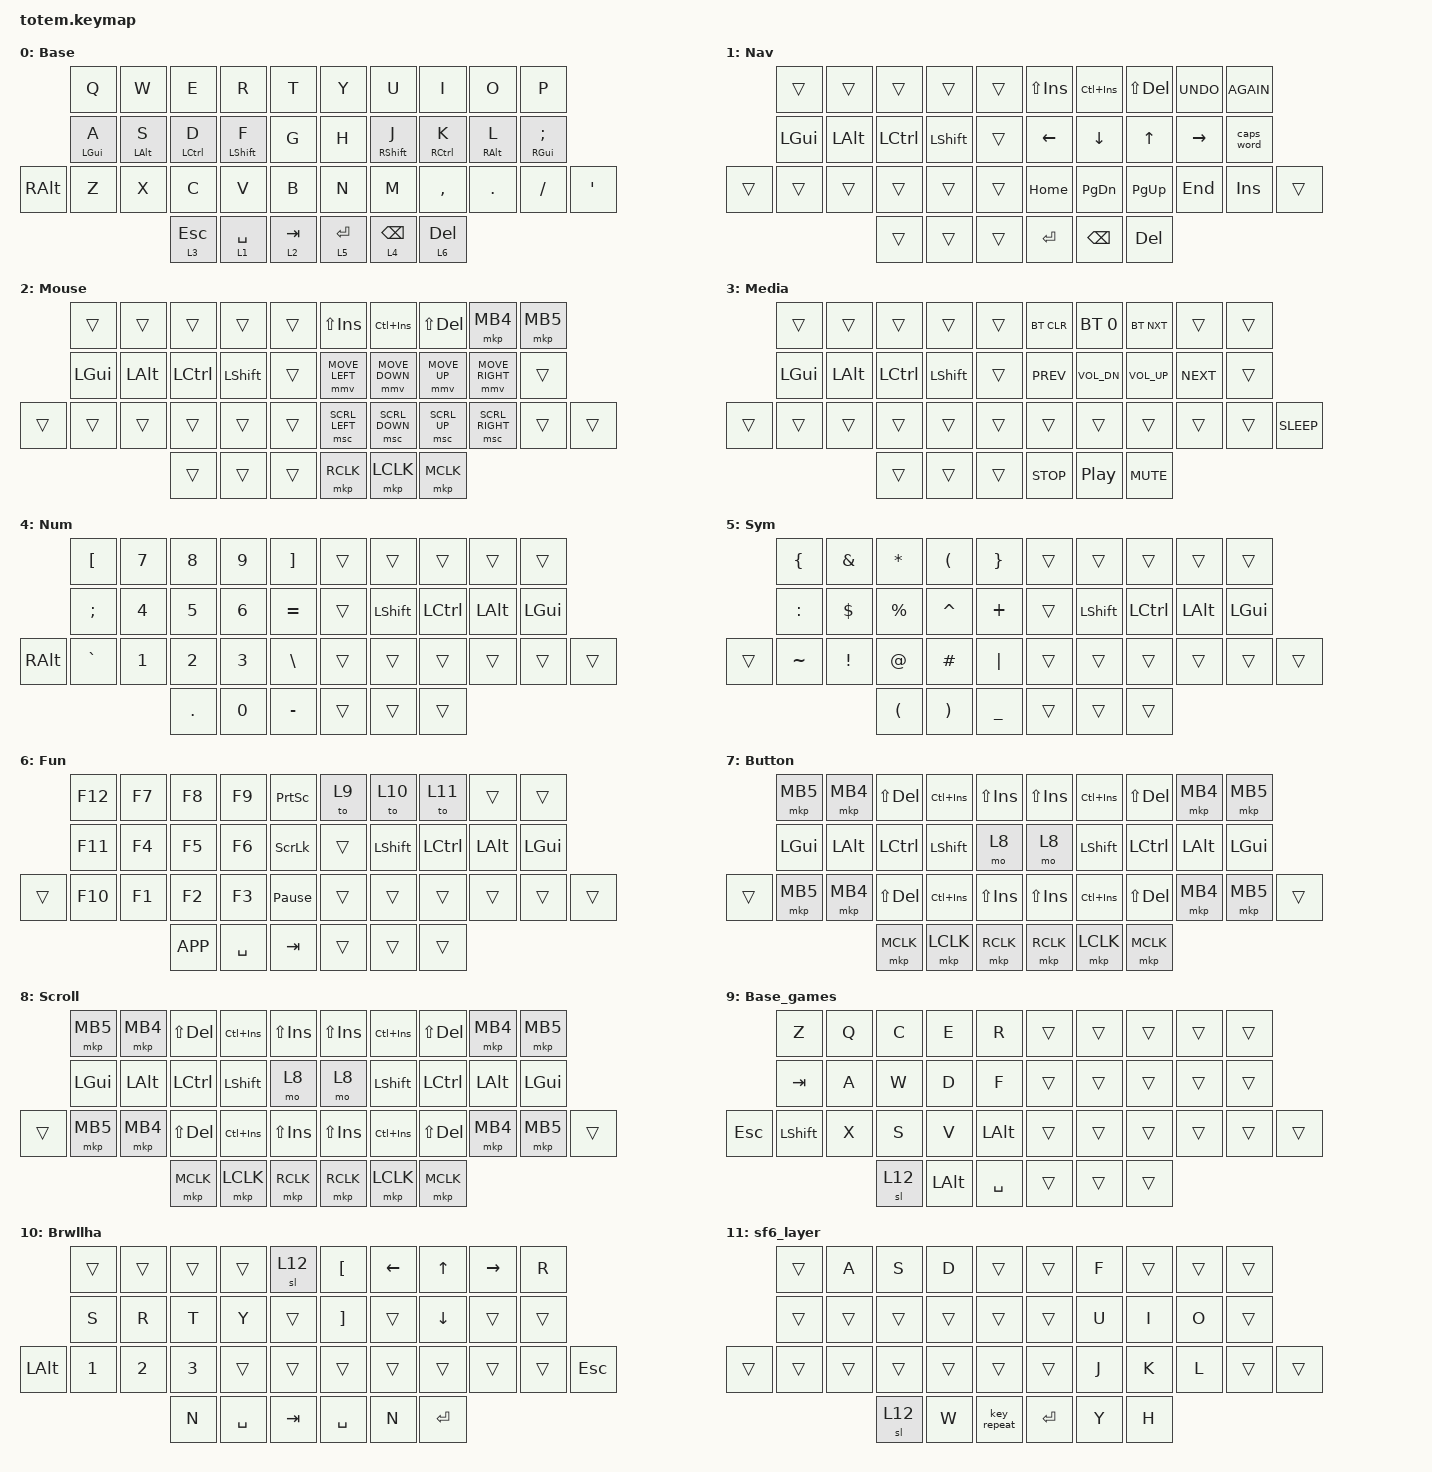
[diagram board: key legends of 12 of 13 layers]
//
//                                                        ▀▀▀▀▀     ▀▀▀▀▀          ▀▀█▀▀
//                                                        ▄▀▀▀▄  ▄  ▄▀▀▀▄  ▄  ▄▀▀▀▄  █  ▄▀▀▀▄
//                                                        █   █  █  █   █  █  █   █  █  █   █
//                                                         ▀▀▀   █   ▀▀▀   █   ▀▀▀   ▀   ▀▀▀
//                                                               █      ▄▄▄█▄▄▄    █   █  
//                                                               ▀      █  █  █     █▄█
//                                                             ▀▀▀▀▀    █  █  █      ▀
//                                                                      ▀  ▀  ▀
//
// ▄▄▄▄▄▄▄▄▄▄▄▄▄▄▄▄▄▄▄▄▄▄▄▄▄▄▄▄▄▄▄▄▄▄▄▄▄▄▄▄▄▄▄▄▄▄▄▄▄▄▄▄▄▄▄▄▄▄▄▄▄▄▄▄▄▄▄▄▄▄▄▄▄▄▄▄▄▄▄▄▄▄▄▄▄▄▄▄▄▄▄▄▄▄▄▄▄▄▄▄▄▄▄▄▄▄▄▄▄▄▄▄▄▄▄▄▄▄▄▄▄▄▄▄▄▄▄▄▄▄▄▄▄▄▄▄▄▄▄▄▄▄▄▄▄▄▄▄▄

#include <behaviors.dtsi>
#include <dt-bindings/zmk/bt.h>
#include <dt-bindings/zmk/keys.h>
#include <dt-bindings/zmk/pointing.h>

#define BASE        0
#define NAV         1
#define MOUSE       2
#define MEDIA       3
#define NUM         4
#define SYM         5
#define FUN         6
#define BUTTON      7
#define BASE_GAMES  9
#define BRWLLHA    10
#define GAME_PLUS  11

// Key position definitions for 38-key Totem layout

#define KEYS_L 0 1 2 3 4 10 11 12 13 14 20 21 22 23 24 25  // left hand
#define KEYS_R 5 6 7 8 9 15 16 17 18 19 26 27 28 29 30 31  // right hand
#define THUMBS 32 33 34 35 36 37                           // thumbs

&mt {
    quick-tap-ms = <100>;
    global-quick-tap;
    flavor = "tap-preferred";
    tapping-term-ms = <170>;
};

&lt {
    tapping-term-ms = <240>;
    flavor = "balanced";
    quick-tap-ms = <150>;
};

/ {
    behaviors {
        // Timeless homerow mods for left hand
        // require-prior-idle-ms = 10500 / WPM (adjust based on typing speed)
        // Same-hand modifiers enabled (no hold-trigger restrictions)

        hml: homerow_mods_left {
            compatible = "zmk,behavior-hold-tap";
            label = "HOMEROW_MODS_LEFT";
            #binding-cells = <2>;
            flavor = "tap-preferred";
            tapping-term-ms = <250>;
            quick-tap-ms = <165>;
            require-prior-idle-ms = <20>;
            bindings = <&kp>, <&kp>;
        };

        // Timeless homerow mods for right hand
        // Urob's timeless config: opposite hand trigger only

        hmr: homerow_mods_right {
            compatible = "zmk,behavior-hold-tap";
            label = "HOMEROW_MODS_RIGHT";
            #binding-cells = <2>;
            flavor = "tap-preferred";
            tapping-term-ms = <250>;
            quick-tap-ms = <165>;
            require-prior-idle-ms = <20>;
            bindings = <&kp>, <&kp>;

            hold-trigger-key-positions = <KEYS_L THUMBS>;
            hold-trigger-on-release;
        };
    };

    combos {
        compatible = "zmk,combos";

        shift_caps_word_combo {
            bindings = <&caps_word>;
            key-positions = <13 16>;
            timeout-ms = <100>;
            require-prior-idle-ms = <150>;
            layers = <0>;
        };
    };

    keymap {
        compatible = "zmk,keymap";

        base_layer {
            display-name = "Base";
            bindings = <
               &kp Q        &kp W        &kp E         &kp R         &kp T        &kp Y      &kp U         &kp I         &kp O        &kp P
               &hml LGUI A  &hml LALT S  &hml LCTRL D  &hml LSHFT F  &kp G        &kp H      &hmr RSHFT J  &hmr RCTRL K  &hmr RALT L  &hmr RGUI SEMICOLON
&kp RIGHT_ALT  &kp Z        &kp X        &kp C         &kp V         &kp B        &kp N      &kp M         &kp COMMA     &kp DOT      &kp SLASH            &kp SQT
                                         &lt 3 ESC     &lt 1 SPACE   &lt 2 TAB    &lt 5 RET  &lt 4 BSPC    &lt 6 DEL
            >;
        };

        nav_layer {
            display-name = "Nav";
            bindings = <
        &trans    &trans    &trans     &trans     &trans    &kp LS(INS)  &kp LC(INS)  &kp LS(DEL)  &kp K_UNDO  &kp K_AGAIN
        &kp LGUI  &kp LALT  &kp LCTRL  &kp LSHFT  &trans    &kp LEFT     &kp DOWN     &kp UP       &kp RIGHT   &caps_word
&trans  &trans    &trans    &trans     &trans     &trans    &kp HOME     &kp PG_DN    &kp PG_UP    &kp END     &kp INS      &trans
                            &trans     &trans     &trans    &kp RET      &kp BSPC     &kp DEL
            >;
        };

        mouse_layer {
            display-name = "Mouse";
            bindings = <
        &trans    &trans    &trans     &trans     &trans    &kp LS(INS)     &kp LC(INS)     &kp LS(DEL)   &mkp MB4         &mkp MB5
        &kp LGUI  &kp LALT  &kp LCTRL  &kp LSHFT  &trans    &mmv MOVE_LEFT  &mmv MOVE_DOWN  &mmv MOVE_UP  &mmv MOVE_RIGHT  &trans
&trans  &trans    &trans    &trans     &trans     &trans    &msc SCRL_LEFT  &msc SCRL_DOWN  &msc SCRL_UP  &msc SCRL_RIGHT  &trans    &trans
                            &trans     &trans     &trans    &mkp RCLK       &mkp LCLK       &mkp MCLK
            >;
        };

        media_layer {
            display-name = "Media";
            bindings = <
        &trans    &trans    &trans     &trans     &trans    &bt BT_CLR  &bt BT_SEL 0  &bt BT_NXT    &trans      &trans
        &kp LGUI  &kp LALT  &kp LCTRL  &kp LSHFT  &trans    &kp C_PREV  &kp C_VOL_DN  &kp C_VOL_UP  &kp C_NEXT  &trans
&trans  &trans    &trans    &trans     &trans     &trans    &trans      &trans        &trans        &trans      &trans  &kp C_SLEEP
                            &trans     &trans     &trans    &kp C_STOP  &kp C_PP      &kp C_MUTE
            >;
        };

        num_layer {
            display-name = "Num";
            bindings = <
          &kp LBKT   &kp N7  &kp N8   &kp N9  &kp RBKT     &trans  &trans     &trans     &trans    &trans
          &kp SEMI   &kp N4  &kp N5   &kp N6  &kp EQUAL    &trans  &kp LSHFT  &kp LCTRL  &kp LALT  &kp LGUI
&kp RALT  &kp GRAVE  &kp N1  &kp N2   &kp N3  &kp BSLH     &trans  &trans     &trans     &trans    &trans    &trans
                             &kp DOT  &kp N0  &kp MINUS    &trans  &trans     &trans
            >;
        };

        sym_layer {
            display-name = "Sym";
            bindings = <
        &kp LBRC   &kp AMPS  &kp ASTRK  &kp LPAR   &kp RBRC     &trans  &trans     &trans     &trans    &trans
        &kp COLON  &kp DLLR  &kp PRCNT  &kp CARET  &kp PLUS     &trans  &kp LSHFT  &kp LCTRL  &kp LALT  &kp LGUI
&trans  &kp TILDE  &kp EXCL  &kp AT     &kp HASH   &kp PIPE     &trans  &trans     &trans     &trans    &trans    &trans
                             &kp LPAR   &kp RPAR   &kp UNDER    &trans  &trans     &trans
            >;
        };

        fun_layer {
            display-name = "Fun";
            bindings = <
        &kp F12  &kp F7  &kp F8     &kp F9     &kp PSCRN          &to 9   &to 10     &to 11     &trans    &trans
        &kp F11  &kp F4  &kp F5     &kp F6     &kp SLCK           &trans  &kp LSHFT  &kp LCTRL  &kp LALT  &kp LGUI
&trans  &kp F10  &kp F1  &kp F2     &kp F3     &kp PAUSE_BREAK    &trans  &trans     &trans     &trans    &trans    &trans
                         &kp K_APP  &kp SPACE  &kp TAB            &trans  &trans     &trans
            >;
        };

        button_layer {
            display-name = "Button";
            bindings = <
        &mkp MB5  &mkp MB4  &kp LS(DEL)  &kp LC(INS)  &kp LS(INS)    &kp LS(INS)  &kp LC(INS)  &kp LS(DEL)  &mkp MB4  &mkp MB5
        &kp LGUI  &kp LALT  &kp LCTRL    &kp LSHFT    &mo 8          &mo 8        &kp LSHFT    &kp LCTRL    &kp LALT  &kp LGUI
&trans  &mkp MB5  &mkp MB4  &kp LS(DEL)  &kp LC(INS)  &kp LS(INS)    &kp LS(INS)  &kp LC(INS)  &kp LS(DEL)  &mkp MB4  &mkp MB5  &trans
                            &mkp MCLK    &mkp LCLK    &mkp RCLK      &mkp RCLK    &mkp LCLK    &mkp MCLK
            >;
        };

        scroll_layer {
            display-name = "Scroll";
            bindings = <
        &mkp MB5  &mkp MB4  &kp LS(DEL)  &kp LC(INS)  &kp LS(INS)    &kp LS(INS)  &kp LC(INS)  &kp LS(DEL)  &mkp MB4  &mkp MB5
        &kp LGUI  &kp LALT  &kp LCTRL    &kp LSHFT    &mo 8          &mo 8        &kp LSHFT    &kp LCTRL    &kp LALT  &kp LGUI
&trans  &mkp MB5  &mkp MB4  &kp LS(DEL)  &kp LC(INS)  &kp LS(INS)    &kp LS(INS)  &kp LC(INS)  &kp LS(DEL)  &mkp MB4  &mkp MB5  &trans
                            &mkp MCLK    &mkp LCLK    &mkp RCLK      &mkp RCLK    &mkp LCLK    &mkp MCLK
            >;
        };

        base_games_layer {
            display-name = "Base_games";
            bindings = <
            &kp Z       &kp Q  &kp C   &kp E     &kp R           &trans  &trans  &trans  &trans  &trans
            &kp TAB     &kp A  &kp W   &kp D     &kp F           &trans  &trans  &trans  &trans  &trans
&kp ESCAPE  &kp LSHIFT  &kp X  &kp S   &kp V     &kp LEFT_ALT    &trans  &trans  &trans  &trans  &trans  &trans
                               &sl 12  &kp LALT  &kp SPACE       &trans  &trans  &trans
            >;
        };

        brwllha_layer {
            display-name = "Brwllha";
            bindings = <
          &trans        &trans        &trans        &trans     &sl 12     &kp LEFT_BRACKET   &kp LEFT_ARROW  &kp UP_ARROW    &kp RIGHT_ARROW  &kp R
          &kp S         &kp R         &kp T         &kp Y      &trans     &kp RIGHT_BRACKET  &trans          &kp DOWN_ARROW  &trans           &trans
&kp LALT  &kp NUMBER_1  &kp NUMBER_2  &kp NUMBER_3  &trans     &trans     &trans             &trans          &trans          &trans           &trans  &kp ESC
                                      &kp N         &kp SPACE  &kp TAB    &kp SPACE          &kp N           &kp ENTER
            >;
        };

        sf6_layer {
            bindings = <
        &trans  &kp A   &kp S   &kp D   &trans         &trans     &kp F  &trans  &trans  &trans
        &trans  &trans  &trans  &trans  &trans         &trans     &kp U  &kp I   &kp O   &trans
&trans  &trans  &trans  &trans  &trans  &trans         &trans     &kp J  &kp K   &kp L   &trans  &trans
                        &sl 12  &kp W   &key_repeat    &kp ENTER  &kp Y  &kp H
            >;
        };

        game_plus_layer {
            display-name = "Game_plus";
            bindings = <
       &kp NUMBER_1  &kp NUMBER_2  &kp NUMBER_3  &kp NUMBER_4  &kp NUMBER_5    &kp F1      &kp F2             &kp F3           &kp F4      &kp F5
       &kp NUMBER_6  &kp NUMBER_7  &kp NUMBER_8  &kp NUMBER_9  &kp NUMBER_0    &kp C_PREV  &kp C_VOLUME_DOWN  &kp C_VOLUME_UP  &kp C_NEXT  &trans
&kp L  &kp O         &kp Y         &kp K         &kp G         &kp T           &to 0       &trans             &kp C_PP         &trans      &trans  &kp LA(F4)
                                   &kp J         &kp I         &kp M           &to 0       &trans             &trans
            >;
        };
    };
};
